# PIC32CX5109BZ36048_SL3 register map
Vendor: Microchip Technology; Series: PIC32CXBZ36; File version: 0
CPU: CM4 r0p1, little endian, MPU, FPU, 3 interrupt priority bits, 43 interrupts
Registers are 32-bit, read-write, reset 0x0 unless marked. A register's access mark holds for its fields unless they carry their own. Offsets are from the block's base; [hi:lo] are bit positions; {n}, {i} and the like mark numbered series.

## QSPI — Quad SPI interface
Base 0x42000000
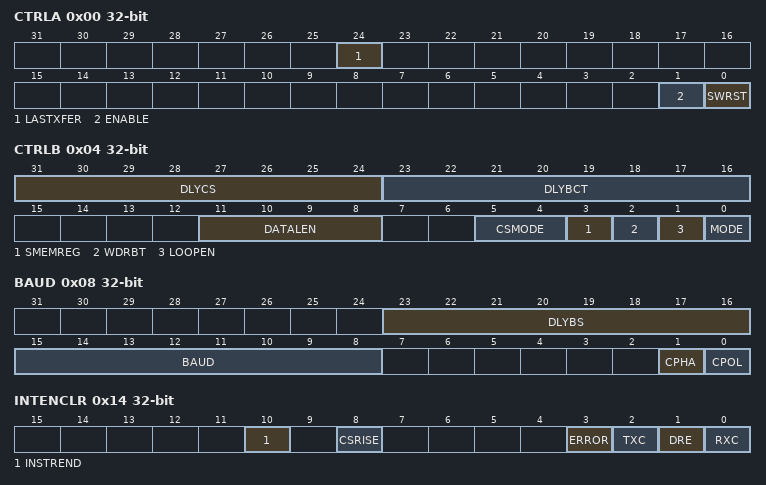
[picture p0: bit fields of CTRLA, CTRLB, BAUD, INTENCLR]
0x00 CTRLA — Control A
  [24] LASTXFER — Last Transfer
  [1] ENABLE
  [0] SWRST — Software Reset
0x04 CTRLB — Control B
  [31:24] DLYCS — Minimum Inactive CS Delay
  [23:16] DLYBCT — Delay Between Consecutive Transfers
  [11:8] DATALEN — Data Length
    0=8BITS (8-bits transfer); 1=9BITS (9 bits transfer); {v}={v+8}BITS ({v+8}-bits transfer) (v=2..8)
  [5:4] CSMODE — Chip Select Mode
    0=NORELOAD (The chip select is deasserted if TD has not been reloaded before the end of the current transfer.); 1=LASTXFER (The chip select is deasserted when the bit LASTXFER is written at 1 and the character written in TD has been transferred.); 2=SYSTEMATICALLY (The chip select is deasserted systematically after each transfer.)
  [3] SMEMREG — Serial Memory reg
  [2] WDRBT — Wait Data Read Before Transfer
  [1] LOOPEN — Local Loopback Enable
    0=DISABLED (Local Loopback is disabled); 1=ENABLED (Local Loopback is enabled)
  [0] MODE — Serial Memory Mode
    0=SPI (SPI operating mode); 1=MEMORY (Serial Memory operating mode)
0x08 BAUD — Baud Rate
  [23:16] DLYBS — Delay Before SCK
  [15:8] BAUD — Serial Clock Baud Rate
  [1] CPHA — Clock Phase
  [0] CPOL — Clock Polarity
0x0C RXDATA ro — Receive Data
  [15:0] DATA
0x10 TXDATA wo — Transmit Data
  [15:0] DATA
0x14 INTENCLR write-1-clears — Interrupt Enable Clear
  [10] INSTREND — Instruction End Interrupt Disable
  [8] CSRISE — Chip Select Rise Interrupt Disable
  [3] ERROR — Overrun Error Interrupt Disable
  [2] TXC — Transmission Complete Interrupt Disable
  [1] DRE — Transmit Data Register Empty Interrupt Disable
  [0] RXC — Receive Data Register Full Interrupt Disable
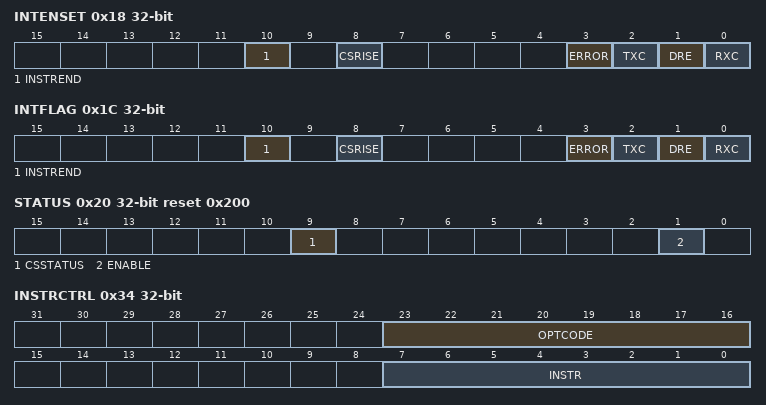
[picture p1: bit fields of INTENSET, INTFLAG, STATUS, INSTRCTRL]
0x18 INTENSET write-1-sets — Interrupt Enable Set
  [10] INSTREND — Instruction End Interrupt Enable
  [8] CSRISE — Chip Select Rise Interrupt Enable
  [3] ERROR — Overrun Error Interrupt Enable
  [2] TXC — Transmission Complete Interrupt Enable
  [1] DRE — Transmit Data Register Empty Interrupt Enable
  [0] RXC — Receive Data Register Full Interrupt Enable
0x1C INTFLAG write-1-clears — Interrupt Flag Status and Clear
  [10] INSTREND — Instruction End
  [8] CSRISE — Chip Select Rise
  [3] ERROR — Overrun Error
  [2] TXC — Transmission Complete
  [1] DRE — Transmit Data Register Empty
  [0] RXC — Receive Data Register Full
0x20 STATUS ro reset 0x200
  [9] CSSTATUS — Chip Select
  [1] ENABLE
0x30 INSTRADDR — Instruction Address
  [31:0] ADDR
0x34 INSTRCTRL — Instruction Code
  [23:16] OPTCODE — Option Code
  [7:0] INSTR — Instruction Code
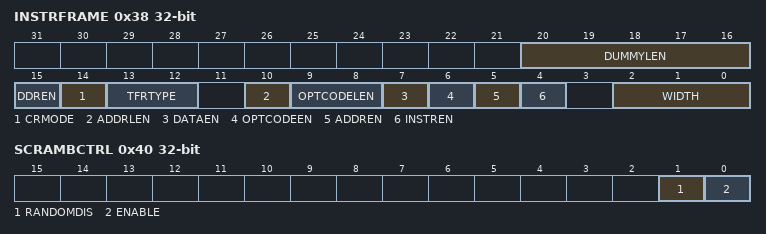
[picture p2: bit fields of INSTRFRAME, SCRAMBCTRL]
0x38 INSTRFRAME — Instruction Frame
  [20:16] DUMMYLEN — Dummy Cycles Length
  [15] DDREN — Double Data Rate Enable
  [14] CRMODE — Continuous Read Mode
  [13:12] TFRTYPE — Data Transfer Type
    0=READ (Read transfer from the serial memory.Scrambling is not performed.Read at random location (fetch) in the serial flash memory is not possible.); 1=READMEMORY (Read data transfer from the serial memory.If enabled, scrambling is performed.Read at random location (fetch) in the serial flash memory is possible.); 2=WRITE (Write transfer into the serial memory.Scrambling is not performed.); 3=WRITEMEMORY (Write data transfer into the serial memory.If enabled, scrambling is performed.)
  [10] ADDRLEN — Address Length
    0=24BITS (24-bits address length); 1=32BITS (32-bits address length)
  [9:8] OPTCODELEN — Option Code Length
    0=1BIT (1-bit length option code); 1=2BITS (2-bits length option code); 2=4BITS (4-bits length option code); 3=8BITS (8-bits length option code)
  [7] DATAEN — Data Enable
  [6] OPTCODEEN — Option Enable
  [5] ADDREN — Address Enable
  [4] INSTREN — Instruction Enable
  [2:0] WIDTH — Instruction Code, Address, Option Code and Data Width
    0=SINGLE_BIT_SPI (Instruction: Single-bit SPI / Address-Option: Single-bit SPI / Data: Single-bit SPI); 1=DUAL_OUTPUT (Instruction: Single-bit SPI / Address-Option: Single-bit SPI / Data: Dual SPI); 2=QUAD_OUTPUT (Instruction: Single-bit SPI / Address-Option: Single-bit SPI / Data: Quad SPI); 3=DUAL_IO (Instruction: Single-bit SPI / Address-Option: Dual SPI / Data: Dual SPI); 4=QUAD_IO (Instruction: Single-bit SPI / Address-Option: Quad SPI / Data: Quad SPI); 5=DUAL_CMD (Instruction: Dual SPI / Address-Option: Dual SPI / Data: Dual SPI); 6=QUAD_CMD (Instruction: Quad SPI / Address-Option: Quad SPI / Data: Quad SPI)
0x40 SCRAMBCTRL — Scrambling Mode
  [1] RANDOMDIS — Scrambling/Unscrambling Random Value Disable
  [0] ENABLE — Scrambling/Unscrambling Enable
0x44 SCRAMBKEY wo — Scrambling Key
  [31:0] KEY — Scrambling User Key
